# ATmega16U4 device description
Architecture: AVR8; Family: megaAVR
Registers are 8-bit, access not given, no defined reset value unless marked. A register's access mark holds for its fields unless they carry their own. Offsets are from the block's base; [hi:lo] are bit positions; {n}, {i} and the like mark numbered series.

## CPU — CPU Registers
Instances: CPU 0x00
Parameters: CORE_VERSION=V3
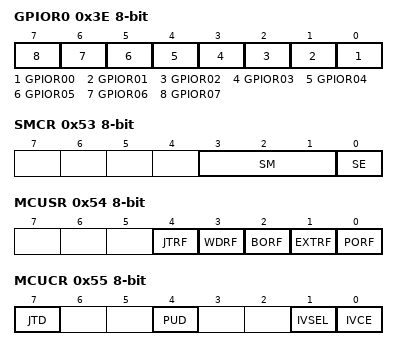
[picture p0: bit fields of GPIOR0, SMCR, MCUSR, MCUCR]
0x3E GPIOR0 — General Purpose IO Register 0
  [n] GPIOR{n:02} (n=0..7) — General Purpose IO Register 0 bit {n}
0x4A GPIOR1 — General Purpose IO Register 1
  [7:0] GPIOR (bit 10 of the value upward) — General Purpose IO Register 1 bis
0x4B GPIOR2 — General Purpose IO Register 2
  [7:0] GPIOR (bit 20 of the value upward) — General Purpose IO Register 2 bis
0x53 SMCR — Sleep Mode Control Register
  [3:1] SM — Sleep Mode Select bits
    0=IDLE; 1=ADC (ADC Noise Reduction (If Available)); 2=PDOWN (Power Down); 3=PSAVE (Power Save); 6=STDBY (Standby); 7=ESTDBY (Extended Standby)
  [0] SE — Sleep Enable
0x54 MCUSR — MCU Status Register
  [4] JTRF — JTAG Reset Flag
  [3] WDRF — Watchdog Reset Flag
  [2] BORF — Brown-out Reset Flag
  [1] EXTRF — External Reset Flag
  [0] PORF — Power-on reset flag
0x55 MCUCR — MCU Control Register
  [7] JTD — JTAG Interface Disable
  [4] PUD — Pull-up disable
  [1] IVSEL — Interrupt Vector Select
  [0] IVCE — Interrupt Vector Change Enable
0x5B RAMPZ — Extended Z-pointer Register for ELPM/SPM
  [1:0] RAMPZ — Extended Z-Pointer Value
    0=Default value of Z-pointer MSB's
0x5C EIND bits used 0 — Extended Indirect Register
0x5D SP 16-bit — Stack Pointer
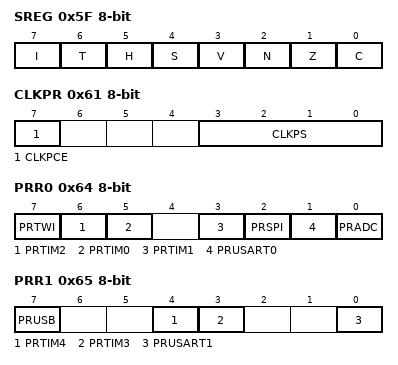
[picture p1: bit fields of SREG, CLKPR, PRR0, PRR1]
0x5F SREG — Status Register
  [7] I — Global Interrupt Enable
  [6] T — Bit Copy Storage
  [5] H — Half Carry Flag
  [4] S — Sign Bit
  [3] V — Two's Complement Overflow Flag
  [2] N — Negative Flag
  [1] Z — Zero Flag
  [0] C — Carry Flag
0x61 CLKPR
  [7] CLKPCE
  [3:0] CLKPS
    0=1; 1=2; 2=4; 3=8; 4=16; 5=32; 6=64; 7=128; 8=256
0x64 PRR0 — Power Reduction Register0
  [7] PRTWI — Power Reduction TWI
  [6] PRTIM2 — Power Reduction Timer/Counter2
  [5] PRTIM0 — Power Reduction Timer/Counter0
  [3] PRTIM1 — Power Reduction Timer/Counter1
  [2] PRSPI — Power Reduction Serial Peripheral Interface
  [1] PRUSART0 — Power Reduction USART
  [0] PRADC — Power Reduction ADC
0x65 PRR1 — Power Reduction Register1
  [7] PRUSB — Power Reduction USB
  [4] PRTIM4 — Power Reduction Timer/Counter4
  [3] PRTIM3 — Power Reduction Timer/Counter3
  [0] PRUSART1 — Power Reduction USART1
0x66 OSCCAL — Oscillator Calibration Value
  [7:0] OSCCAL — Oscillator Calibration
0x67 RCCTRL — Oscillator Control Register
  [0] RCFREQ
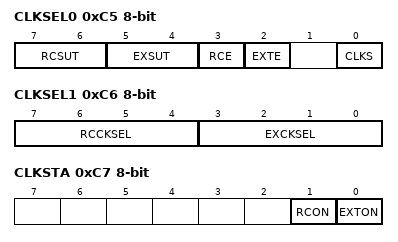
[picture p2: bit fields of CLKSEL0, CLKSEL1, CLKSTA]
0xC5 CLKSEL0
  [7:6] RCSUT, [5:4] EXSUT, [3] RCE, [2] EXTE, [0] CLKS
0xC6 CLKSEL1
  [7:4] RCCKSEL, [3:0] EXCKSEL
0xC7 CLKSTA
  [1] RCON, [0] EXTON
Value list OSCCAL_VALUE_ADDRESSES: 0=8_0_MHz

## PLL — Phase Locked Loop
Instances: PLL 0x00
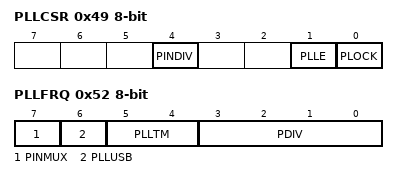
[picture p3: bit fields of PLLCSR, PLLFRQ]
0x49 PLLCSR — PLL Status and Control register
  [4] PINDIV — PLL prescaler Bit 2
  [1] PLLE — PLL Enable Bit
  [0] PLOCK — PLL Lock Status Bit
0x52 PLLFRQ — PLL Frequency Control Register
  [7] PINMUX, [6] PLLUSB, [5:4] PLLTM, [3:0] PDIV

## USB_DEVICE — USB Device Registers
Instances: USB_DEVICE 0x00
0xD7 UHWCON
  [0] UVREGE
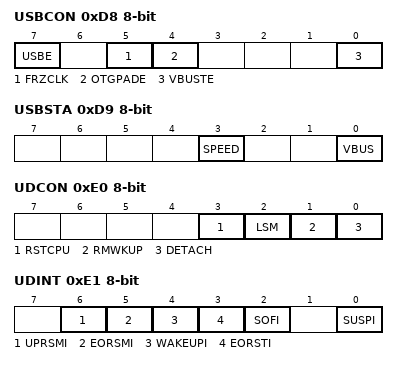
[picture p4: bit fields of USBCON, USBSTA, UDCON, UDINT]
0xD8 USBCON — USB General Control Register
  [7] USBE, [5] FRZCLK, [4] OTGPADE, [0] VBUSTE
0xD9 USBSTA
  [3] SPEED, [0] VBUS
0xDA USBINT
  [0] VBUSTI
0xE0 UDCON
  [3] RSTCPU
  [2] LSM — USB low speed mode
  [1] RMWKUP
  [0] DETACH
0xE1 UDINT
  [6] UPRSMI, [5] EORSMI, [4] WAKEUPI, [3] EORSTI, [2] SOFI, [0] SUSPI
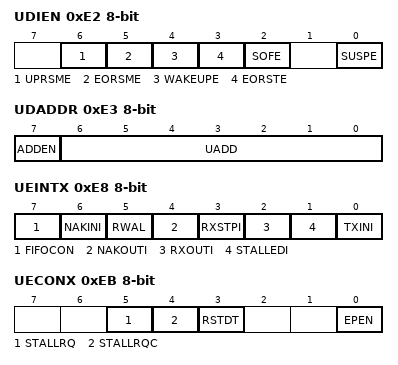
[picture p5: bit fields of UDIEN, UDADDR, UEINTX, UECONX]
0xE2 UDIEN
  [6] UPRSME, [5] EORSME, [4] WAKEUPE, [3] EORSTE, [2] SOFE, [0] SUSPE
0xE3 UDADDR
  [7] ADDEN, [6:0] UADD
0xE4 UDFNUM 16-bit
  [10:0] FNUM — Frame number value
0xE6 UDMFN
  [4] FNCERR
0xE8 UEINTX
  [7] FIFOCON, [6] NAKINI, [5] RWAL, [4] NAKOUTI, [3] RXSTPI, [2] RXOUTI, [1] STALLEDI, [0] TXINI
0xE9 UENUM
  [2:0] UENUM
0xEA UERST
  [6:0] EPRST
0xEB UECONX
  [5] STALLRQ, [4] STALLRQC, [3] RSTDT, [0] EPEN
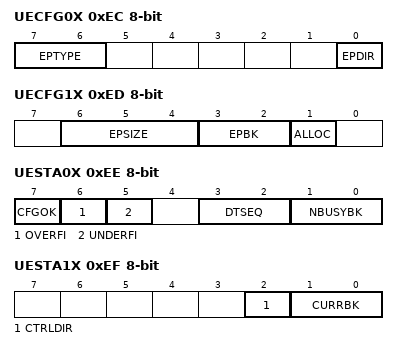
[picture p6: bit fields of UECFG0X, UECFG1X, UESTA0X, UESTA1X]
0xEC UECFG0X
  [7:6] EPTYPE, [0] EPDIR
0xED UECFG1X
  [6:4] EPSIZE, [3:2] EPBK, [1] ALLOC
0xEE UESTA0X
  [7] CFGOK, [6] OVERFI, [5] UNDERFI, [3:2] DTSEQ, [1:0] NBUSYBK
0xEF UESTA1X
  [2] CTRLDIR, [1:0] CURRBK
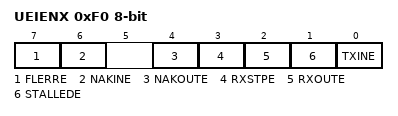
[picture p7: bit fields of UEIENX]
0xF0 UEIENX
  [7] FLERRE, [6] NAKINE, [4] NAKOUTE, [3] RXSTPE, [2] RXOUTE, [1] STALLEDE, [0] TXINE
0xF1 UEDATX
  [7:0] DAT
0xF2 UEBCLX
  [7:0] BYCT — Byte count bits
0xF3 UEBCHX
  [2:0] BYCT (bit 8 of the value upward) — Byte count bits
0xF4 UEINT
  [6:0] EPINT — Endpoint interrupt bits
